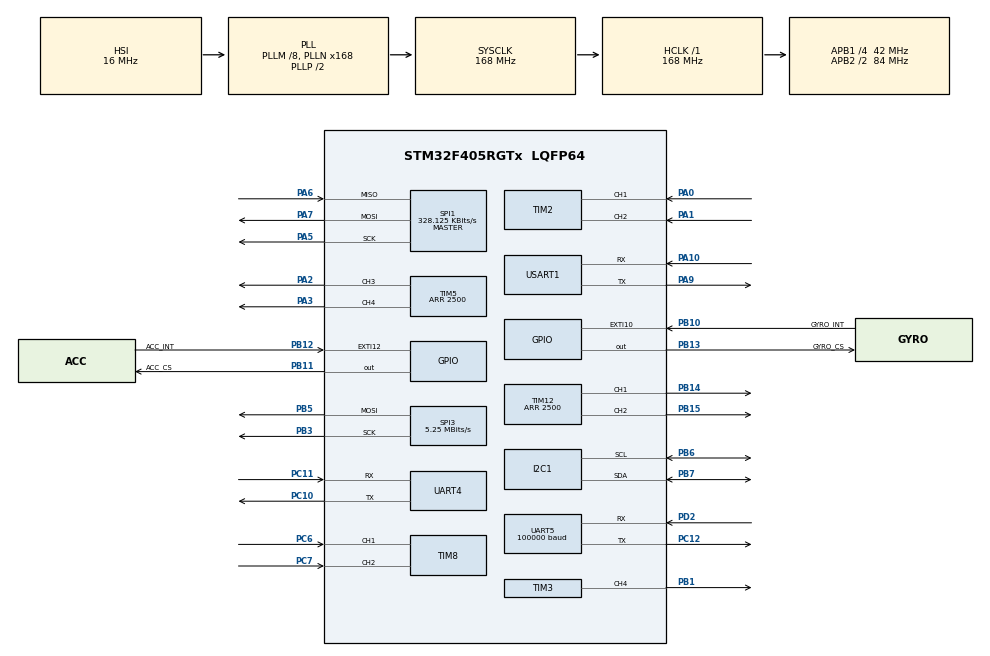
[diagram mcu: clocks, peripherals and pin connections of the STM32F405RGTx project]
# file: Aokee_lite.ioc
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Dma.I2C1_RX.5.Direction=DMA_PERIPH_TO_MEMORY
Dma.I2C1_RX.5.FIFOMode=DMA_FIFOMODE_DISABLE
Dma.I2C1_RX.5.Instance=DMA1_Stream5
Dma.I2C1_RX.5.MemDataAlignment=DMA_MDATAALIGN_BYTE
Dma.I2C1_RX.5.MemInc=DMA_MINC_ENABLE
Dma.I2C1_RX.5.Mode=DMA_NORMAL
Dma.I2C1_RX.5.PeriphDataAlignment=DMA_PDATAALIGN_BYTE
Dma.I2C1_RX.5.PeriphInc=DMA_PINC_DISABLE
Dma.I2C1_RX.5.Priority=DMA_PRIORITY_MEDIUM
Dma.I2C1_TX.4.Direction=DMA_MEMORY_TO_PERIPH
Dma.I2C1_TX.4.FIFOMode=DMA_FIFOMODE_DISABLE
Dma.I2C1_TX.4.Instance=DMA1_Stream6
Dma.I2C1_TX.4.MemDataAlignment=DMA_MDATAALIGN_BYTE
Dma.I2C1_TX.4.MemInc=DMA_MINC_ENABLE
Dma.I2C1_TX.4.Mode=DMA_NORMAL
Dma.I2C1_TX.4.PeriphDataAlignment=DMA_PDATAALIGN_BYTE
Dma.I2C1_TX.4.PeriphInc=DMA_PINC_DISABLE
Dma.I2C1_TX.4.Priority=DMA_PRIORITY_MEDIUM
Dma.Request0=USART1_RX
Dma.Request1=USART1_TX
Dma.Request2=SPI1_RX
Dma.Request3=SPI1_TX
Dma.Request4=I2C1_TX
Dma.Request5=I2C1_RX
Dma.Request6=UART5_RX
Dma.Request7=UART4_RX
Dma.Request8=UART4_TX
Dma.SPI1_RX.2.Direction=DMA_PERIPH_TO_MEMORY
Dma.SPI1_RX.2.FIFOMode=DMA_FIFOMODE_DISABLE
Dma.SPI1_RX.2.Instance=DMA2_Stream0
Dma.SPI1_RX.2.MemDataAlignment=DMA_MDATAALIGN_BYTE
Dma.SPI1_RX.2.MemInc=DMA_MINC_ENABLE
Dma.SPI1_RX.2.Mode=DMA_NORMAL
Dma.SPI1_RX.2.PeriphDataAlignment=DMA_PDATAALIGN_BYTE
Dma.SPI1_RX.2.PeriphInc=DMA_PINC_DISABLE
Dma.SPI1_RX.2.Priority=DMA_PRIORITY_VERY_HIGH
Dma.SPI1_TX.3.Direction=DMA_MEMORY_TO_PERIPH
Dma.SPI1_TX.3.FIFOMode=DMA_FIFOMODE_DISABLE
Dma.SPI1_TX.3.Instance=DMA2_Stream3
Dma.SPI1_TX.3.MemDataAlignment=DMA_MDATAALIGN_BYTE
Dma.SPI1_TX.3.MemInc=DMA_MINC_ENABLE
Dma.SPI1_TX.3.Mode=DMA_NORMAL
Dma.SPI1_TX.3.PeriphDataAlignment=DMA_PDATAALIGN_BYTE
Dma.SPI1_TX.3.PeriphInc=DMA_PINC_DISABLE
Dma.SPI1_TX.3.Priority=DMA_PRIORITY_HIGH
Dma.UART4_RX.7.Direction=DMA_PERIPH_TO_MEMORY
Dma.UART4_RX.7.FIFOMode=DMA_FIFOMODE_DISABLE
Dma.UART4_RX.7.Instance=DMA1_Stream2
Dma.UART4_RX.7.MemDataAlignment=DMA_MDATAALIGN_BYTE
Dma.UART4_RX.7.MemInc=DMA_MINC_ENABLE
Dma.UART4_RX.7.Mode=DMA_NORMAL
Dma.UART4_RX.7.PeriphDataAlignment=DMA_PDATAALIGN_BYTE
Dma.UART4_RX.7.PeriphInc=DMA_PINC_DISABLE
Dma.UART4_RX.7.Priority=DMA_PRIORITY_MEDIUM
Dma.UART4_TX.8.Direction=DMA_MEMORY_TO_PERIPH
Dma.UART4_TX.8.FIFOMode=DMA_FIFOMODE_DISABLE
Dma.UART4_TX.8.Instance=DMA1_Stream4
Dma.UART4_TX.8.MemDataAlignment=DMA_MDATAALIGN_BYTE
Dma.UART4_TX.8.MemInc=DMA_MINC_ENABLE
Dma.UART4_TX.8.Mode=DMA_NORMAL
Dma.UART4_TX.8.PeriphDataAlignment=DMA_PDATAALIGN_BYTE
Dma.UART4_TX.8.PeriphInc=DMA_PINC_DISABLE
Dma.UART4_TX.8.Priority=DMA_PRIORITY_MEDIUM
Dma.UART5_RX.6.Direction=DMA_PERIPH_TO_MEMORY
Dma.UART5_RX.6.FIFOMode=DMA_FIFOMODE_DISABLE
Dma.UART5_RX.6.Instance=DMA1_Stream0
Dma.UART5_RX.6.MemDataAlignment=DMA_MDATAALIGN_BYTE
Dma.UART5_RX.6.MemInc=DMA_MINC_ENABLE
Dma.UART5_RX.6.Mode=DMA_NORMAL
Dma.UART5_RX.6.PeriphDataAlignment=DMA_PDATAALIGN_BYTE
Dma.UART5_RX.6.PeriphInc=DMA_PINC_DISABLE
Dma.UART5_RX.6.Priority=DMA_PRIORITY_HIGH
Dma.USART1_RX.0.Direction=DMA_PERIPH_TO_MEMORY
Dma.USART1_RX.0.FIFOMode=DMA_FIFOMODE_DISABLE
Dma.USART1_RX.0.Instance=DMA2_Stream2
Dma.USART1_RX.0.MemDataAlignment=DMA_MDATAALIGN_BYTE
Dma.USART1_RX.0.MemInc=DMA_MINC_ENABLE
Dma.USART1_RX.0.Mode=DMA_NORMAL
Dma.USART1_RX.0.PeriphDataAlignment=DMA_PDATAALIGN_BYTE
Dma.USART1_RX.0.PeriphInc=DMA_PINC_DISABLE
Dma.USART1_RX.0.Priority=DMA_PRIORITY_MEDIUM
Dma.USART1_TX.1.Direction=DMA_MEMORY_TO_PERIPH
Dma.USART1_TX.1.FIFOMode=DMA_FIFOMODE_DISABLE
Dma.USART1_TX.1.Instance=DMA2_Stream7
Dma.USART1_TX.1.MemDataAlignment=DMA_MDATAALIGN_BYTE
Dma.USART1_TX.1.MemInc=DMA_MINC_ENABLE
Dma.USART1_TX.1.Mode=DMA_NORMAL
Dma.USART1_TX.1.PeriphDataAlignment=DMA_PDATAALIGN_BYTE
Dma.USART1_TX.1.PeriphInc=DMA_PINC_DISABLE
Dma.USART1_TX.1.Priority=DMA_PRIORITY_MEDIUM
I2C1.I2C_Mode=I2C_Fast
Mcu.Family=STM32F4
Mcu.Name=STM32F405RGTx
Mcu.Package=LQFP64
NVIC.DMA1_Stream0_IRQn=true\:0\:0\:false\:false\:true\:false\:true\:true
NVIC.DMA1_Stream2_IRQn=true\:0\:0\:false\:false\:true\:false\:true\:true
NVIC.DMA1_Stream4_IRQn=true\:0\:0\:false\:false\:true\:false\:true\:true
NVIC.DMA1_Stream5_IRQn=true\:0\:0\:false\:false\:true\:false\:true\:true
NVIC.DMA1_Stream6_IRQn=true\:0\:0\:false\:false\:true\:false\:true\:true
NVIC.DMA2_Stream0_IRQn=true\:0\:0\:false\:false\:true\:false\:true\:true
NVIC.DMA2_Stream2_IRQn=true\:0\:0\:false\:false\:true\:false\:true\:true
NVIC.DMA2_Stream3_IRQn=true\:0\:0\:false\:false\:true\:false\:true\:true
NVIC.DMA2_Stream7_IRQn=true\:0\:0\:false\:false\:true\:false\:true\:true
NVIC.PriorityGroup=NVIC_PRIORITYGROUP_4
NVIC.TIM8_TRG_COM_TIM14_IRQn=true\:15\:0\:false\:false\:true\:false\:true\:true
NVIC.TimeBase=TIM8_TRG_COM_TIM14_IRQn
NVIC.TimeBaseIP=TIM14
NVIC.UART4_IRQn=true\:0\:0\:false\:false\:true\:true\:true\:true
NVIC.UART5_IRQn=true\:0\:0\:false\:false\:true\:true\:true\:true
NVIC.USART1_IRQn=true\:0\:0\:false\:false\:true\:true\:true\:true
PA0-WKUP.Signal=S_TIM2_CH1_ETR
PA1.Signal=S_TIM2_CH2
PA10.Mode=Asynchronous
PA10.Signal=USART1_RX
PA13.Mode=Serial_Wire
PA13.Signal=SYS_JTMS-SWDIO
PA14.Mode=Serial_Wire
PA14.Signal=SYS_JTCK-SWCLK
PA2.Signal=S_TIM5_CH3
PA3.Signal=S_TIM5_CH4
PA5.GPIO_PuPd=GPIO_PULLUP
PA5.Mode=Full_Duplex_Master
PA5.Signal=SPI1_SCK
PA6.GPIO_PuPd=GPIO_PULLUP
PA6.Mode=Full_Duplex_Master
PA6.Signal=SPI1_MISO
PA7.GPIO_PuPd=GPIO_PULLUP
PA7.Mode=Full_Duplex_Master
PA7.Signal=SPI1_MOSI
PA9.Mode=Asynchronous
PA9.Signal=USART1_TX
PB1.Signal=S_TIM3_CH4
PB10.GPIO_Label=GYRO_INT
PB10.Signal=GPXTI10
PB11.GPIO_Label=ACC_CS
PB11.Signal=GPIO_Output
PB12.GPIO_Label=ACC_INT
PB12.Signal=GPXTI12
PB13.GPIO_Label=GYRO_CS
PB13.Signal=GPIO_Output
PB14.Signal=S_TIM12_CH1
PB15.Signal=S_TIM12_CH2
PB3.Mode=TX_Only_Simplex_Unidirect_Master
PB3.Signal=SPI3_SCK
PB5.Mode=TX_Only_Simplex_Unidirect_Master
PB5.Signal=SPI3_MOSI
PB6.Mode=I2C
PB6.Signal=I2C1_SCL
PB7.Mode=I2C
PB7.Signal=I2C1_SDA
PC10.Mode=Asynchronous
PC10.Signal=UART4_TX
PC11.Mode=Asynchronous
PC11.Signal=UART4_RX
PC12.Mode=Asynchronous
PC12.Signal=UART5_TX
PC6.Signal=S_TIM8_CH1
PC7.Signal=S_TIM8_CH2
PD2.Mode=Asynchronous
PD2.Signal=UART5_RX
PH0-OSC_IN.Mode=HSE-External-Oscillator
PH0-OSC_IN.Signal=RCC_OSC_IN
PH1-OSC_OUT.Mode=HSE-External-Oscillator
PH1-OSC_OUT.Signal=RCC_OSC_OUT
ProjectManager.HeapSize=0x200
ProjectManager.StackSize=0x400
ProjectManager.TargetToolchain=Makefile
RCC.48MHZClocksFreq_Value=84000000
RCC.AHBFreq_Value=168000000
RCC.APB1CLKDivider=RCC_HCLK_DIV4
RCC.APB1Freq_Value=42000000
RCC.APB1TimFreq_Value=84000000
RCC.APB2CLKDivider=RCC_HCLK_DIV2
RCC.APB2Freq_Value=84000000
RCC.APB2TimFreq_Value=168000000
RCC.CortexFreq_Value=168000000
RCC.HCLKFreq_Value=168000000
RCC.HSE_VALUE=12000000
RCC.HSI_VALUE=16000000
RCC.LSE_VALUE=32768
RCC.PLLM=8
RCC.PLLN=168
RCC.SYSCLKFreq_VALUE=168000000
RCC.SYSCLKSource=RCC_SYSCLKSOURCE_PLLCLK
RCC.VCOOutputFreq_Value=336000000
SH.S_TIM12_CH1.0=TIM12_CH1,PWM Generation1 CH1
SH.S_TIM12_CH2.0=TIM12_CH2,PWM Generation2 CH2
SH.S_TIM2_CH1_ETR.0=TIM2_CH1,Encoder_Interface
SH.S_TIM2_CH2.0=TIM2_CH2,Encoder_Interface
SH.S_TIM3_CH4.0=TIM3_CH4,PWM Generation4 CH4
SH.S_TIM5_CH3.0=TIM5_CH3,PWM Generation3 CH3
SH.S_TIM5_CH4.0=TIM5_CH4,PWM Generation4 CH4
SH.S_TIM8_CH1.0=TIM8_CH1,Encoder_Interface
SH.S_TIM8_CH2.0=TIM8_CH2,Encoder_Interface
SPI1.BaudRatePrescaler=SPI_BAUDRATEPRESCALER_256
SPI1.CLKPhase=SPI_PHASE_2EDGE
SPI1.CLKPolarity=SPI_POLARITY_HIGH
SPI1.CalculateBaudRate=328.125 KBits/s
SPI1.Direction=SPI_DIRECTION_2LINES
SPI1.Mode=SPI_MODE_MASTER
SPI1.VirtualType=VM_MASTER
SPI3.BaudRatePrescaler=SPI_BAUDRATEPRESCALER_8
SPI3.CLKPhase=SPI_PHASE_2EDGE
SPI3.CLKPolarity=SPI_POLARITY_LOW
SPI3.CalculateBaudRate=5.25 MBits/s
SPI3.Direction=SPI_DIRECTION_2LINES
SPI3.Mode=SPI_MODE_MASTER
SPI3.VirtualType=VM_MASTER
TIM12.Channel-PWM\ Generation1\ CH1=TIM_CHANNEL_1
TIM12.Channel-PWM\ Generation2\ CH2=TIM_CHANNEL_2
TIM12.Period=2500
TIM3.Channel-PWM\ Generation4\ CH4=TIM_CHANNEL_4
TIM5.Channel-PWM\ Generation3\ CH3=TIM_CHANNEL_3
TIM5.Channel-PWM\ Generation4\ CH4=TIM_CHANNEL_4
TIM5.Period=2500
UART4.VirtualMode=Asynchronous
UART5.BaudRate=100000
UART5.VirtualMode=Asynchronous
USART1.VirtualMode=VM_ASYNC
VP_SYS_VS_tim14.Mode=TIM14
board=custom

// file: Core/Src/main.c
/* USER CODE BEGIN Header */
/**
  ******************************************************************************
  * @file           : main.c
  * @brief          : Main program body
  ******************************************************************************
  * @attention
  *
  * Copyright (c) 2024 STMicroelectronics.
  * All rights reserved.
  *
  * This software is licensed under terms that can be found in the LICENSE file
  * in the root directory of this software component.
  * If no LICENSE file comes with this software, it is provided AS-IS.
  *
  ******************************************************************************
  */
/* USER CODE END Header */
#include "main.h"
#include "dma.h"
#include "i2c.h"
#include "spi.h"
#include "tim.h"
#include "usart.h"
#include "gpio.h"

/* USER CODE BEGIN Includes */
#include "compatible.h"
/* USER CODE END Includes */

void SystemClock_Config(void);

int main(void)
{

  /* MCU Configuration--------------------------------------------------------*/

  /* Reset of all peripherals, Initializes the Flash interface and the Systick. */
  HAL_Init();

  /* Configure the system clock */
  SystemClock_Config();

  /* Initialize all configured peripherals */
  MX_GPIO_Init();
  MX_DMA_Init();
  MX_USART1_UART_Init();
  MX_SPI1_Init();
  MX_I2C1_Init();
  MX_SPI3_Init();
  MX_TIM2_Init();
  MX_TIM3_Init();
  MX_TIM5_Init();
  MX_TIM8_Init();
  MX_TIM12_Init();
  MX_UART4_Init();
  MX_UART5_Init();
  /* USER CODE BEGIN 2 */
    main_entry();
  /* USER CODE END 2 */

  /* Infinite loop */
    while (1) {

    }
}

void SystemClock_Config(void)
{
  RCC_OscInitTypeDef RCC_OscInitStruct = {0};
  RCC_ClkInitTypeDef RCC_ClkInitStruct = {0};

  /** Configure the main internal regulator output voltage
  */
  __HAL_RCC_PWR_CLK_ENABLE();
  __HAL_PWR_VOLTAGESCALING_CONFIG(PWR_REGULATOR_VOLTAGE_SCALE1);

  /** Initializes the RCC Oscillators according to the specified parameters
  * in the RCC_OscInitTypeDef structure.
  */
  RCC_OscInitStruct.OscillatorType = RCC_OSCILLATORTYPE_HSI;
  RCC_OscInitStruct.HSIState = RCC_HSI_ON;
  RCC_OscInitStruct.HSICalibrationValue = RCC_HSICALIBRATION_DEFAULT;
  RCC_OscInitStruct.PLL.PLLState = RCC_PLL_ON;
  RCC_OscInitStruct.PLL.PLLSource = RCC_PLLSOURCE_HSI;
  RCC_OscInitStruct.PLL.PLLM = 8;
  RCC_OscInitStruct.PLL.PLLN = 168;
  RCC_OscInitStruct.PLL.PLLP = RCC_PLLP_DIV2;
  RCC_OscInitStruct.PLL.PLLQ = 4;
  if (HAL_RCC_OscConfig(&RCC_OscInitStruct) != HAL_OK)
  {
    Error_Handler();
  }

  /** Initializes the CPU, AHB and APB buses clocks
  */
  RCC_ClkInitStruct.ClockType = RCC_CLOCKTYPE_HCLK|RCC_CLOCKTYPE_SYSCLK
                              |RCC_CLOCKTYPE_PCLK1|RCC_CLOCKTYPE_PCLK2;
  RCC_ClkInitStruct.SYSCLKSource = RCC_SYSCLKSOURCE_PLLCLK;
  RCC_ClkInitStruct.AHBCLKDivider = RCC_SYSCLK_DIV1;
  RCC_ClkInitStruct.APB1CLKDivider = RCC_HCLK_DIV4;
  RCC_ClkInitStruct.APB2CLKDivider = RCC_HCLK_DIV2;

  if (HAL_RCC_ClockConfig(&RCC_ClkInitStruct, FLASH_LATENCY_5) != HAL_OK)
  {
    Error_Handler();
  }
}

void HAL_TIM_PeriodElapsedCallback(TIM_HandleTypeDef *htim)
{
  if (htim->Instance == TIM14) {
    HAL_IncTick();
  }
}

void Error_Handler(void)
{
    __disable_irq();
    while (1) {
    }
}
